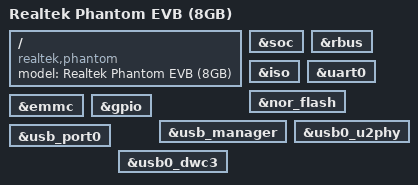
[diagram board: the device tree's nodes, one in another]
// SPDX-License-Identifier: (GPL-2.0-or-later OR BSD-2-Clause)
/*
 * Realtek RTD1501S Phantom EVB
 *
 * Copyright (c) 2024 Realtek Semiconductor Corp.
 */

/dts-v1/;

#include "rtd1501s-phantom.dtsi"

/ {
	compatible = "realtek,phantom", "realtek,rtd1501s";
	model = "Realtek Phantom EVB (8GB)";
};

&soc {
	bootph-all;
};

&rbus {
	bootph-all;
};

&iso {
	bootph-all;
};

&uart0 {
	bootph-all;
	status = "okay";
};

&nor_flash {
	bootph-all;
};

&emmc {
	bootph-all;
};

&gpio {
	bootph-all;
	status = "okay";
};

&usb_manager {
	bootph-all;
};

&usb0_u2phy {
	bootph-all;
};

&usb_port0 {
	bootph-all;
};

&usb0_dwc3 {
	bootph-all;
};
